# D1H.pdf register map
Vendor: Allwinner; Series: D1H.pdf; File version: 0.1
CPU: XuanTie C906 RISC-V CPU 0, little endian, MPU, FPU, double-precision FPU, 0 interrupt priority bits
Registers are 32-bit, read-write, reset 0x0 unless marked. A register's access mark holds for its fields unless they carry their own. Offsets are from the block's base; [hi:lo] are bit positions; lines under a group give offsets from that group; {n}, {i} and the like mark numbered series.

## TCON_TV0
Base 0x05470000
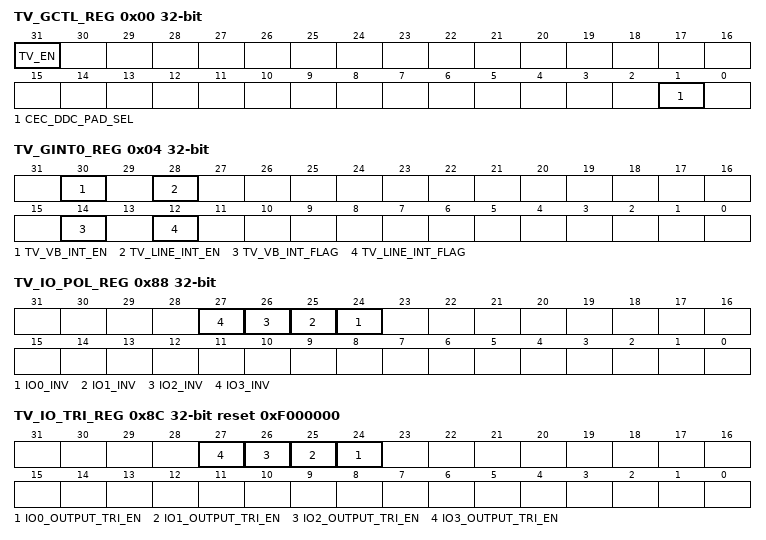
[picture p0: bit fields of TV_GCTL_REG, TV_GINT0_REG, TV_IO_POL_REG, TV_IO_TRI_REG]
0x00 TV_GCTL_REG — TV Global Control Register
  [31] TV_EN — When it is disabled, the module will be reset to idle state. 0: Disable 1: Enable
    0=Disable; 1=Enable
  [1] CEC_DDC_PAD_SEL — CEC DDC PAD Select 1: TCON_TV internal pad for cec scl sal 0: GPIO pad for cec scl sal
    1=TCON_TV (TCON_TV internal pad for cec scl sal); 0=GPIO (GPIO pad for cec scl sal)
0x04 TV_GINT0_REG — TV Global Interrupt Register0
  [30] TV_VB_INT_EN — TV Vb Interrupt Enable 0: Disable 1: Enable
    0=Disable; 1=Enable
  [28] TV_LINE_INT_EN — TV Line Interrupt Enable 0: Disable 1: Enable
    0=Disable; 1=Enable
  [14] TV_VB_INT_FLAG — TV Vb Interrupt Flag Asserted during vertical no-display period every frame. Write 0 to clear it.
  [12] TV_LINE_INT_FLAG — TV Line Interrupt Flag Trigger when SY1 match the current TV scan line Write 0 to clear it.
0x08 TV_GINT1_REG — TV Global Interrupt Register1
  [11:0] TV_LINE_INT_NUM — Scan line for TV line trigger(including inactive lines) Setting it for the specified line for trigger 1. Note: SY1 is writable only when LINE_TRG1 is disabled.
0x40 TV_SRC_CTL_REG — TV Source Control Register
  [2:0] TV_SRC_SEL — TV Source Select 000: DE 001: Color Check 010: Grayscale Check 011: Black by White Check 100: Reserved 101: Reserved 111: Gridding Check
    0=DE; 1=Color Check; 2=Grayscale Check; 3=Black by White Check; 7=Gridding Check
0x88 TV_IO_POL_REG — TV SYNC Signal Polarity Register
  [all] fields
    0=Not_invert; 1=Invert
  [n+24] IO{n}_INV (n=0..3) — IO{n} Invert 0: Not invert 1: Invert
0x8C TV_IO_TRI_REG reset 0xF000000 — TV SYNC Signal IO Control Register
  [all] fields
    1=Disable; 0=Enable
  [n+24] IO{n}_OUTPUT_TRI_EN (n=0..3) — IO{n} Output Trigger Enable 1: Disable 0: Enable
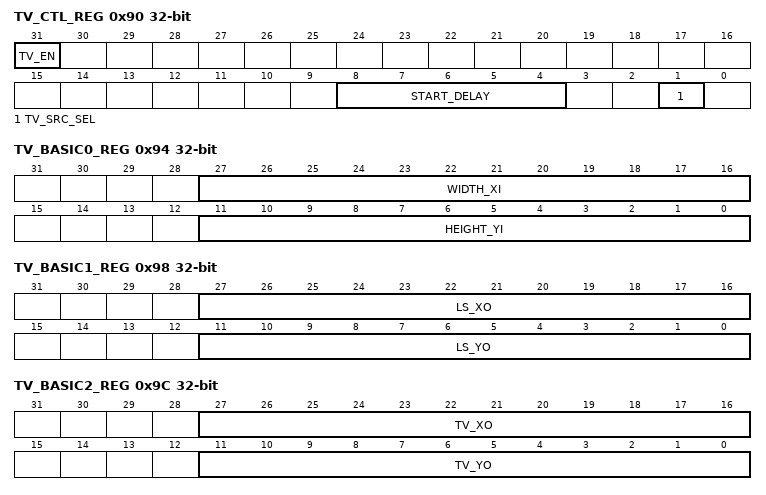
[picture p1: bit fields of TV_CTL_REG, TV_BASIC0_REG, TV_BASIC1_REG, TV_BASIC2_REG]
0x90 TV_CTL_REG — TV Control Register
  [31] TV_EN — When enable TCON_TV, this bit and the 0x0000[bit31] need to be enabled. 0: Disable 1: Enable
    0=Disable; 1=Enable
  [8:4] START_DELAY — This is for DE0 and DE1.
  [1] TV_SRC_SEL — TV Source Select 0: Reserved 1: BLUE data Note: The priority of this bit is higher than TV_SRC_SEL(bit[2:0]) in TV_SRC_CTL_REG.
    1=BLUE data Note: The priority of this bit is higher than TV_SRC_SEL(bit[2:0]) in TV_SRC_CTL_REG
0x94 TV_BASIC0_REG — TV Basic Timing Register0
  [27:16] WIDTH_XI — Source Width Is X+1
  [11:0] HEIGHT_YI — Source Height Is Y+1
0x98 TV_BASIC1_REG — TV Basic Timing Register1
  [27:16] LS_XO — Width Is LS_XO+1
  [11:0] LS_YO — Width Is LS_YO+1 Note: This version LS_YO = TV_YI
0x9C TV_BASIC2_REG — TV Basic Timing Register2
  [27:16] TV_XO — Width is TV_XO+1
  [11:0] TV_YO — Height is TV_YO+1
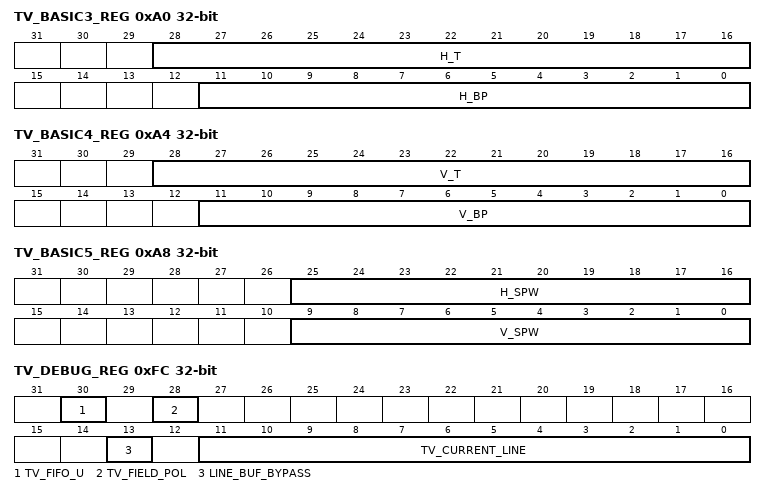
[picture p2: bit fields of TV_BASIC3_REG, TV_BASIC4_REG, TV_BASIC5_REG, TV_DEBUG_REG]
0xA0 TV_BASIC3_REG — TV Basic Timing Register3
  [28:16] H_T — Horizontal total time Thcycle = (HT+1) * Thdclk
  [11:0] H_BP — Horizontal back porch Thbp = (HBP +1) * Thdclk
0xA4 TV_BASIC4_REG — TV Basic Timing Register4
  [28:16] V_T — horizontal total time (in HD line) Tvt = VT/2 * Th
  [11:0] V_BP — horizontal back porch (in HD line) Tvbp = (VBP +1) * Th
0xA8 TV_BASIC5_REG — TV Basic Timing Register5
  [25:16] H_SPW — Horizontal Sync Pulse Width (in dclk) Thspw = (HSPW+1) * Tdclk Note: HT> (HSPW+1)
  [9:0] V_SPW — Vertical Sync Pulse Width (in lines) Tvspw = (VSPW+1) * Th Note: VT/2 > (VSPW+1)
0xFC TV_DEBUG_REG — TV Debug Register
  [30] TV_FIFO_U — TV FIFO Underflow
  [28] TV_FIELD_POL ro — TV Field Polarity 0: Second field 1: First field
    0=Second; 1=First
  [13] LINE_BUF_BYPASS — Line Buf fer Bypass 0: Used 1: Bypass
    0=Used; 1=Bypass
  [11:0] TV_CURRENT_LINE ro
0x100 TV_CEU_CTL_REG — TV CEU Control Register
  [31] CEU_EN — CEU Enable 0: Bypass 1: Enable
    0=Bypass; 1=Enable
{0x110+4i} TV_CEU_COEF_MUL_REG[{i}] (i=0..10) — TV_CEU_COEF_MUL_REG[{i}]
  [8] CEU_COEF_MUL_VALUE — Note: 1.CEU_Coef_Mul_Value only can be 0 or 1. 2. REG Map: N=0: Rr N=1: Rg N=2: Rb N=4: Gr N=5: Gg N=6: Gb N=8: Br N=9: Bg N=10: Bb
{0x140+4i} _N[{i}] (i=0..2) group
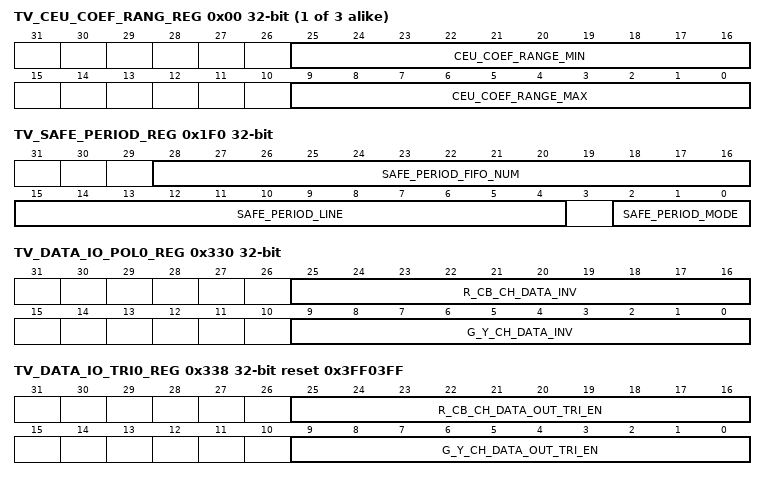
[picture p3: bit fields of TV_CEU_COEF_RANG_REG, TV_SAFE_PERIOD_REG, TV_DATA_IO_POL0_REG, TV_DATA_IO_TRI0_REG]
  0x00 TV_CEU_COEF_RANG_REG — TV CEU Coefficient Register2
    [25:16] CEU_COEF_RANGE_MIN — Unsigned 10-bit Value, range of [0, 1023]
    [9:0] CEU_COEF_RANGE_MAX — Unsigned 10-bit Value, range of [0, 1023]
  0x1C4 TV_FILL_BEGIN_REG — TV Fill Data Begin Register
    [23:0] FILL_BEGIN
  0x1C8 TV_FILL_END_REG — TV Fill Data End Register
    [23:0] FILL_END
  0x1CC TV_FILL_DATA_REG — TV Fill Data Value Register
    [29:0] FILL_VALUE
0x1F0 TV_SAFE_PERIOD_REG — TV Safe Period Register
  [28:16] SAFE_PERIOD_FIFO_NUM — Safe Period FIFO Number
  [15:4] SAFE_PERIOD_LINE
  [2:0] SAFE_PERIOD_MODE — Safe Period Mode 000: unsafe 001: safe 010: safe at line_buf_curr_num > safe_period_fifo_num 011: safe at 2 and safe at sync active 100: safe at line
0x300 TV_FILL_CTL_REG — TV Fill Data Control Register
  [31] TV_FILL_EN — TV Fill Enable 0: Bypass 1: Enable
    0=Bypass; 1=Enable
0x330 TV_DATA_IO_POL0_REG — TCON Data IO Polarity Control0
  [25:16] R_CB_CH_DATA_INV — R CB Channel Data Inv 0: normal polarity 1: invert the specify output
  [9:0] G_Y_CH_DATA_INV — G Y Channel Data Inv 0: normal polarity 1: invert the specify output
0x334 TV_DATA_IO_POL1_REG — TCON Data IO Polarity Control1
  [25:16] B_CR_CH_DATA_INV — B CR CHANNE DATA INV 0: Normal polarity 1: Invert the specify output
0x338 TV_DATA_IO_TRI0_REG reset 0x3FF03FF — TCON Data IO Enable Control0
  [25:16] R_CB_CH_DATA_OUT_TRI_EN — R CB Channel Data Output Trigger Enable 1: Disable 0: Enable
  [9:0] G_Y_CH_DATA_OUT_TRI_EN — G Y Channel Data Output Trigger Enable 1: Disable 0: Enable
0x33C TV_DATA_IO_TRI1_REG reset 0x3FF0000 — TCON Data IO Enable Control1
  [25:16] B_CR_CH_DATA_OUT_TRI_EN — B CR Channel Data Output Trigger Enable 1: Disable 0: Enable
0x340 TV_PIXELDEPTH_MODE_REG — TV Pixeldepth Mode Control Register
  [0] COLORBAR_PD_MODE — Colorbar Pixeldepth mode 0: 8 bit mode When data source is the embedded colorbar, the 8-bit colorbar pattern is transmitted. 1: 10 bit mode When data source is the embedded colorbar, the 10-bit colorbar pattern is transmitted.
    0=8 bit mode When data source is the embedded colorbar, the 8-bit colorbar pattern is transmitted; 1=10 bit mode When data source is the embedded colorbar, the 10-bit colorbar pattern is transmitted
